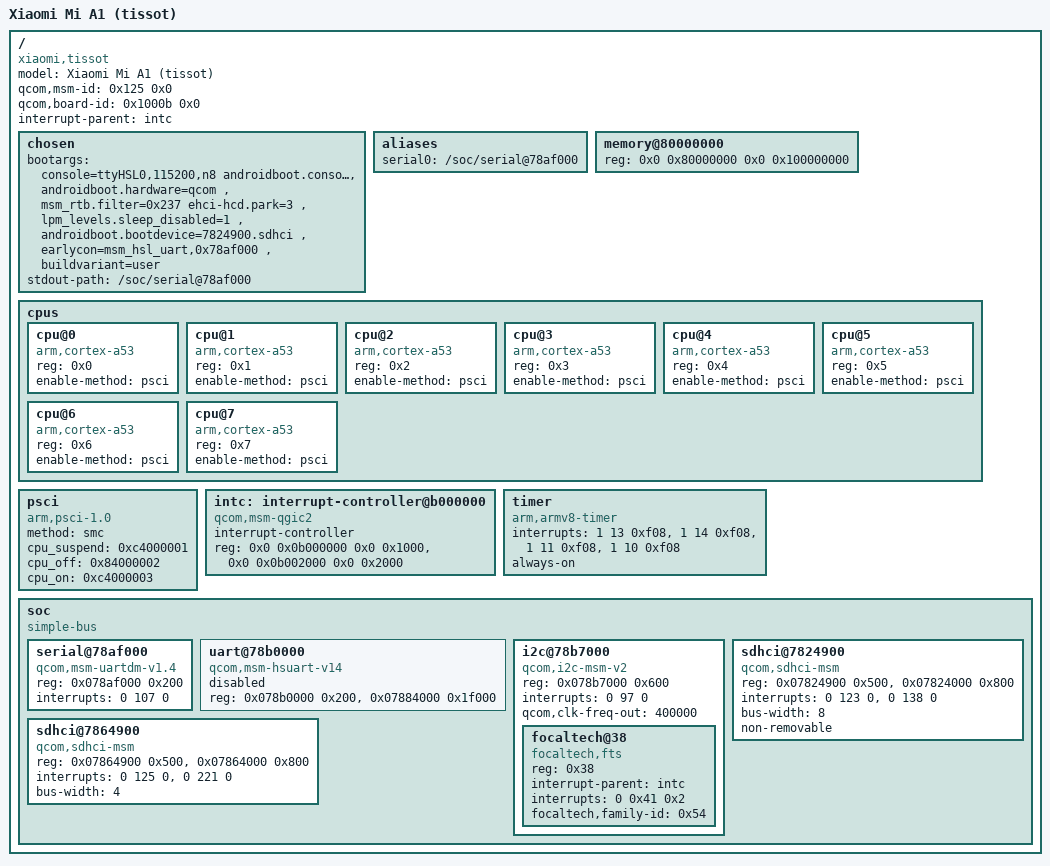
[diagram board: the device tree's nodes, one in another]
/dts-v1/;

/*
 * Xiaomi Mi A1 (tissot) — Qualcomm MSM8953 / Snapdragon 625
 * Auto-generated equivalent of prebuilt/tissot.dtb
 * Generated by tools/build_tissot_dtb.py
 */

/ {
    #address-cells = <2>;
    #size-cells = <2>;
    model = "Xiaomi Mi A1 (tissot)";
    compatible = "xiaomi,tissot", "qcom,msm8953";
    qcom,msm-id = <0x125 0x0>;      /* 293 = MSM8953 */
    qcom,board-id = <0x1000b 0x0>;  /* real tissot value (msm8953-qrd-sku3-tissot.dts) */
    interrupt-parent = <&intc>;

    chosen {
        bootargs = "console=ttyHSL0,115200,n8 androidboot.console=ttyHSL0 "
                   "androidboot.hardware=qcom "
                   "msm_rtb.filter=0x237 ehci-hcd.park=3 "
                   "lpm_levels.sleep_disabled=1 "
                   "androidboot.bootdevice=7824900.sdhci "
                   "earlycon=msm_hsl_uart,0x78af000 "
                   "buildvariant=user";
        stdout-path = "/soc/serial@78af000";
    };

    aliases {
        serial0 = "/soc/serial@78af000";
    };

    memory@80000000 {
        device_type = "memory";
        reg = <0x0 0x80000000 0x0 0x100000000>;
    };

    cpus {
        #address-cells = <1>;
        #size-cells = <0>;

        cpu@0 { device_type = "cpu"; compatible = "arm,cortex-a53"; reg = <0x0>; enable-method = "psci"; };
        cpu@1 { device_type = "cpu"; compatible = "arm,cortex-a53"; reg = <0x1>; enable-method = "psci"; };
        cpu@2 { device_type = "cpu"; compatible = "arm,cortex-a53"; reg = <0x2>; enable-method = "psci"; };
        cpu@3 { device_type = "cpu"; compatible = "arm,cortex-a53"; reg = <0x3>; enable-method = "psci"; };
        cpu@4 { device_type = "cpu"; compatible = "arm,cortex-a53"; reg = <0x4>; enable-method = "psci"; };
        cpu@5 { device_type = "cpu"; compatible = "arm,cortex-a53"; reg = <0x5>; enable-method = "psci"; };
        cpu@6 { device_type = "cpu"; compatible = "arm,cortex-a53"; reg = <0x6>; enable-method = "psci"; };
        cpu@7 { device_type = "cpu"; compatible = "arm,cortex-a53"; reg = <0x7>; enable-method = "psci"; };
    };

    psci {
        compatible = "arm,psci-1.0", "arm,psci-0.2";
        method = "smc";
        cpu_suspend = <0xc4000001>;
        cpu_off     = <0x84000002>;
        cpu_on      = <0xc4000003>;
    };

    intc: interrupt-controller@b000000 {
        compatible = "qcom,msm-qgic2";
        interrupt-controller;
        #interrupt-cells = <3>;
        reg = <0x0 0x0b000000 0x0 0x1000>,
              <0x0 0x0b002000 0x0 0x2000>;
    };

    timer {
        compatible = "arm,armv8-timer";
        interrupts = <1 13 0xf08>, <1 14 0xf08>, <1 11 0xf08>, <1 10 0xf08>;
        always-on;
    };

    soc {
        compatible = "simple-bus";
        #address-cells = <1>;
        #size-cells = <1>;
        ranges;

        serial@78af000 {          /* console / ttyHSL0 */
            compatible = "qcom,msm-uartdm-v1.4", "qcom,msm-uartdm";
            reg = <0x078af000 0x200>;
            interrupts = <0 107 0>;
            status = "okay";
        };

        uart@78b0000 {            /* HSUART, not the console */
            compatible = "qcom,msm-hsuart-v14";
            reg = <0x078b0000 0x200>, <0x07884000 0x1f000>;
            status = "disabled";
        };

        i2c@78b7000 {             /* BLSP1 QUP3 — touch bus (NOT 78b6000) */
            compatible = "qcom,i2c-msm-v2";
            reg = <0x078b7000 0x600>;
            interrupts = <0 97 0>;
            #address-cells = <1>;
            #size-cells = <0>;
            qcom,clk-freq-out = <400000>;
            status = "okay";

            focaltech@38 {        /* FocalTech FT5435 touchscreen */
                compatible = "focaltech,fts";
                reg = <0x38>;
                interrupt-parent = <&intc>;
                interrupts = <0 0x41 0x2>;
                focaltech,family-id = <0x54>;
                status = "okay";
            };
        };

        sdhci@7824900 {           /* eMMC (SDCC1) */
            compatible = "qcom,sdhci-msm";
            reg = <0x07824900 0x500>, <0x07824000 0x800>;
            interrupts = <0 123 0>, <0 138 0>;
            bus-width = <8>;
            non-removable;
            status = "okay";
        };

        sdhci@7864900 {           /* SD card (SDCC2) */
            compatible = "qcom,sdhci-msm";
            reg = <0x07864900 0x500>, <0x07864000 0x800>;
            interrupts = <0 125 0>, <0 221 0>;
            bus-width = <4>;
            status = "okay";
        };
    };
};
